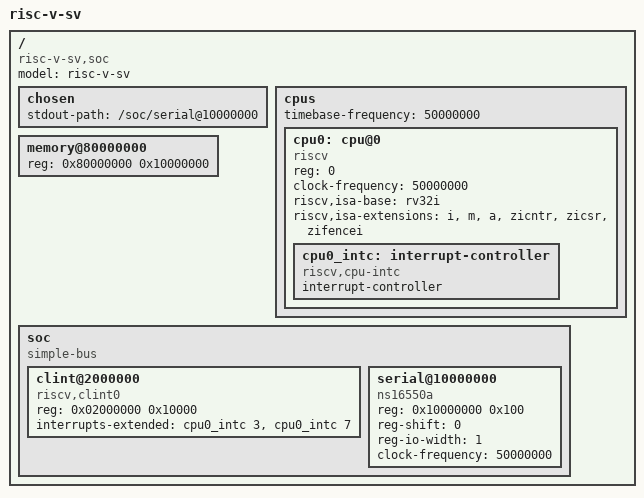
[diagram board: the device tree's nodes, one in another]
/dts-v1/;

// The SoC as built (README "System"): one RV32IMA hart at 50 MHz, 256 MB of
// main memory, the CLINT and the ns16550a-compatible UART. No PLIC yet: the
// UART raises no interrupt.

/ {
	#address-cells = <1>;
	#size-cells = <1>;
	compatible = "risc-v-sv,soc";
	model = "risc-v-sv";

	chosen {
		stdout-path = "/soc/serial@10000000";
	};

	cpus {
		#address-cells = <1>;
		#size-cells = <0>;
		timebase-frequency = <50000000>;

		cpu0: cpu@0 {
			device_type = "cpu";
			compatible = "riscv";
			reg = <0>;
			status = "okay";
			clock-frequency = <50000000>;
			riscv,isa-base = "rv32i";
			riscv,isa-extensions = "i", "m", "a", "zicntr", "zicsr", "zifencei";

			cpu0_intc: interrupt-controller {
				#interrupt-cells = <1>;
				compatible = "riscv,cpu-intc";
				interrupt-controller;
			};
		};
	};

	memory@80000000 {
		device_type = "memory";
		reg = <0x80000000 0x10000000>;
	};

	soc {
		#address-cells = <1>;
		#size-cells = <1>;
		compatible = "simple-bus";
		ranges;

		clint@2000000 {
			compatible = "riscv,clint0";
			reg = <0x02000000 0x10000>;
			interrupts-extended = <&cpu0_intc 3 &cpu0_intc 7>;
		};

		serial@10000000 {
			compatible = "ns16550a";
			reg = <0x10000000 0x100>;
			reg-shift = <0>;
			reg-io-width = <1>;
			clock-frequency = <50000000>;
		};
	};
};
